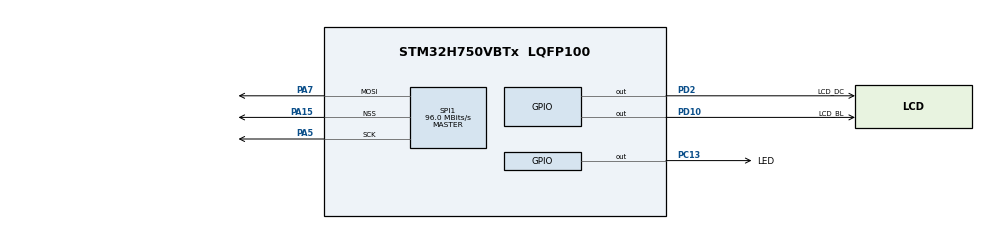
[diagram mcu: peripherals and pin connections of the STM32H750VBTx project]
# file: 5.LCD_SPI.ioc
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Mcu.Family=STM32H7
Mcu.Name=STM32H750VBTx
Mcu.Package=LQFP100
NVIC.PriorityGroup=NVIC_PRIORITYGROUP_4
PA13\ (JTMS/SWDIO).Mode=Serial_Wire
PA13\ (JTMS/SWDIO).Signal=DEBUG_JTMS-SWDIO
PA14\ (JTCK/SWCLK).Mode=Serial_Wire
PA14\ (JTCK/SWCLK).Signal=DEBUG_JTCK-SWCLK
PA15\ (JTDI).GPIO_PuPd=GPIO_PULLUP
PA15\ (JTDI).GPIO_Speed=GPIO_SPEED_FREQ_HIGH
PA15\ (JTDI).Mode=NSS_Signal_Hard_Output
PA15\ (JTDI).Signal=SPI1_NSS
PA5.GPIO_PuPd=GPIO_PULLUP
PA5.GPIO_Speed=GPIO_SPEED_FREQ_HIGH
PA5.Mode=TX_Only_Simplex_Unidirect_Master
PA5.Signal=SPI1_SCK
PA7.GPIO_PuPd=GPIO_PULLUP
PA7.GPIO_Speed=GPIO_SPEED_FREQ_HIGH
PA7.Mode=TX_Only_Simplex_Unidirect_Master
PA7.Signal=SPI1_MOSI
PC13.GPIO_Label=LED
PC13.Signal=GPIO_Output
PD10.GPIO_Label=LCD_BL
PD10.Signal=GPIO_Output
PD2.GPIO_Label=LCD_DC
PD2.Signal=GPIO_Output
ProjectManager.HeapSize=0x200
ProjectManager.StackSize=0x400
ProjectManager.TargetToolchain=MDK-ARM V5.32
RCC.ADCFreq_Value=129000000
RCC.APB1Freq_Value=120000000
RCC.APB2Freq_Value=120000000
RCC.APB3Freq_Value=120000000
RCC.APB4Freq_Value=120000000
RCC.CortexFreq_Value=480000000
RCC.D1PPRE=RCC_APB3_DIV2
RCC.D2PPRE1=RCC_APB1_DIV2
RCC.D2PPRE2=RCC_APB2_DIV2
RCC.D3PPRE=RCC_APB4_DIV2
RCC.DIVM1=4
RCC.DIVN1=60
RCC.DIVQ1=5
RCC.HCLKFreq_Value=240000000
RCC.HPRE=RCC_HCLK_DIV2
RCC.PLLFRACN=0
RCC.SYSCLKFreq_VALUE=480000000
RCC.SYSCLKSource=RCC_SYSCLKSOURCE_PLLCLK
RCC.USBFreq_Value=192000000
SPI1.CLKPhase=SPI_PHASE_2EDGE
SPI1.CLKPolarity=SPI_POLARITY_HIGH
SPI1.CalculateBaudRate=96.0 MBits/s
SPI1.DataSize=SPI_DATASIZE_8BIT
SPI1.Direction=SPI_DIRECTION_2LINES_TXONLY
SPI1.Mode=SPI_MODE_MASTER
SPI1.TIMode=SPI_TIMODE_DISABLE
SPI1.VirtualNSS=VM_NSSHARD
SPI1.VirtualType=VM_MASTER
board=custom

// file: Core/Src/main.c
/* USER CODE BEGIN Header */
/**
  ******************************************************************************
  * @file           : main.c
  * @brief          : Main program body
  ******************************************************************************
  * @attention
  *
  * Copyright (c) 2024 STMicroelectronics.
  * All rights reserved.
  *
  * This software is licensed under terms that can be found in the LICENSE file
  * in the root directory of this software component.
  * If no LICENSE file comes with this software, it is provided AS-IS.
  *
  ******************************************************************************
  */
/* USER CODE END Header */
#include "main.h"
#include "spi.h"
#include "gpio.h"

/* USER CODE BEGIN Includes */
#include "lcd.h"

/* USER CODE END Includes */

void SystemClock_Config(void);

int main(void)
{

  /* MCU Configuration--------------------------------------------------------*/

  /* Reset of all peripherals, Initializes the Flash interface and the Systick. */
  HAL_Init();

  /* Configure the system clock */
  SystemClock_Config();

  /* Initialize all configured peripherals */
  MX_GPIO_Init();
  MX_SPI1_Init();																			//MX配置SPI，模式3，8位
  /* USER CODE BEGIN 2 */
	LCD_Init();																				//LCD初始化
	LCD_Fill(0, 0, 128, 160, WHITE);														//填充白色

	LCD_DrawLine(12,24,116,24,RED);															//划线
	LCD_DrawLine(12,90,116,90,RED);
	LCD_ShowString(24,30,"LCD_W:",RED,WHITE,16,0);											//写汉字
	LCD_ShowIntNum(72,30,LCD_W,3,RED,WHITE,16);												//写数字
	LCD_ShowString(24,50,"LCD_H:",RED,WHITE,16,0);
	LCD_ShowIntNum(72,50,LCD_H,3,RED,WHITE,16);
	LCD_ShowString(12,70,"Hello World!",RED,WHITE,16,0);

  /* USER CODE END 2 */

  /* Infinite loop */
  /* USER CODE BEGIN WHILE */
  while (1)
  {
	  HAL_GPIO_TogglePin(LED_GPIO_Port, LED_Pin);
	  HAL_Delay(500);
    /* USER CODE END WHILE */

  }
}

void SystemClock_Config(void)
{
  RCC_OscInitTypeDef RCC_OscInitStruct = {0};
  RCC_ClkInitTypeDef RCC_ClkInitStruct = {0};

  /** Supply configuration update enable
  */
  HAL_PWREx_ConfigSupply(PWR_LDO_SUPPLY);

  /** Configure the main internal regulator output voltage
  */
  __HAL_PWR_VOLTAGESCALING_CONFIG(PWR_REGULATOR_VOLTAGE_SCALE1);

  while(!__HAL_PWR_GET_FLAG(PWR_FLAG_VOSRDY)) {}

  __HAL_RCC_SYSCFG_CLK_ENABLE();
  __HAL_PWR_VOLTAGESCALING_CONFIG(PWR_REGULATOR_VOLTAGE_SCALE0);

  while(!__HAL_PWR_GET_FLAG(PWR_FLAG_VOSRDY)) {}

  /** Initializes the RCC Oscillators according to the specified parameters
  * in the RCC_OscInitTypeDef structure.
  */
  RCC_OscInitStruct.OscillatorType = RCC_OSCILLATORTYPE_HSI;
  RCC_OscInitStruct.HSIState = RCC_HSI_DIV1;
  RCC_OscInitStruct.HSICalibrationValue = RCC_HSICALIBRATION_DEFAULT;
  RCC_OscInitStruct.PLL.PLLState = RCC_PLL_ON;
  RCC_OscInitStruct.PLL.PLLSource = RCC_PLLSOURCE_HSI;
  RCC_OscInitStruct.PLL.PLLM = 4;
  RCC_OscInitStruct.PLL.PLLN = 60;
  RCC_OscInitStruct.PLL.PLLP = 2;
  RCC_OscInitStruct.PLL.PLLQ = 5;
  RCC_OscInitStruct.PLL.PLLR = 2;
  RCC_OscInitStruct.PLL.PLLRGE = RCC_PLL1VCIRANGE_3;
  RCC_OscInitStruct.PLL.PLLVCOSEL = RCC_PLL1VCOWIDE;
  RCC_OscInitStruct.PLL.PLLFRACN = 0;
  if (HAL_RCC_OscConfig(&RCC_OscInitStruct) != HAL_OK)
  {
    Error_Handler();
  }

  /** Initializes the CPU, AHB and APB buses clocks
  */
  RCC_ClkInitStruct.ClockType = RCC_CLOCKTYPE_HCLK|RCC_CLOCKTYPE_SYSCLK
                              |RCC_CLOCKTYPE_PCLK1|RCC_CLOCKTYPE_PCLK2
                              |RCC_CLOCKTYPE_D3PCLK1|RCC_CLOCKTYPE_D1PCLK1;
  RCC_ClkInitStruct.SYSCLKSource = RCC_SYSCLKSOURCE_PLLCLK;
  RCC_ClkInitStruct.SYSCLKDivider = RCC_SYSCLK_DIV1;
  RCC_ClkInitStruct.AHBCLKDivider = RCC_HCLK_DIV2;
  RCC_ClkInitStruct.APB3CLKDivider = RCC_APB3_DIV2;
  RCC_ClkInitStruct.APB1CLKDivider = RCC_APB1_DIV2;
  RCC_ClkInitStruct.APB2CLKDivider = RCC_APB2_DIV2;
  RCC_ClkInitStruct.APB4CLKDivider = RCC_APB4_DIV2;

  if (HAL_RCC_ClockConfig(&RCC_ClkInitStruct, FLASH_LATENCY_4) != HAL_OK)
  {
    Error_Handler();
  }
}

void Error_Handler(void)
{
  __disable_irq();
  while (1)
  {
  }
}
